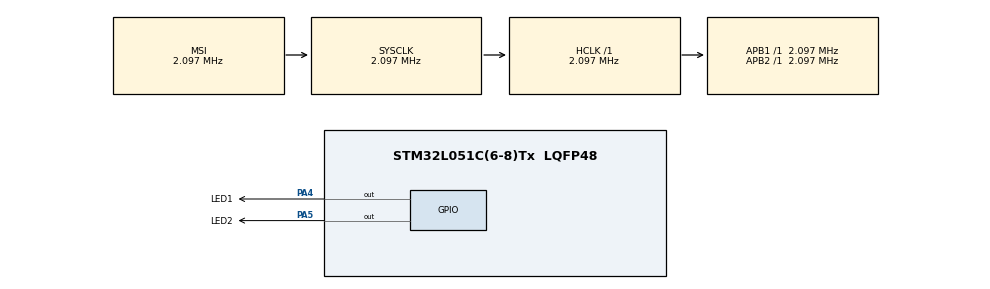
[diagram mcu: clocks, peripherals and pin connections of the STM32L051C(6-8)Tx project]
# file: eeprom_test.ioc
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Mcu.Family=STM32L0
Mcu.Name=STM32L051C(6-8)Tx
Mcu.Package=LQFP48
PA4.GPIO_Label=LED1
PA4.Signal=GPIO_Output
PA5.GPIO_Label=LED2
PA5.Signal=GPIO_Output
ProjectManager.HeapSize=0x200
ProjectManager.StackSize=0x400
ProjectManager.TargetToolchain=STM32CubeIDE
RCC.AHBFreq_Value=2097000
RCC.APB1Freq_Value=2097000
RCC.APB1TimFreq_Value=2097000
RCC.APB2Freq_Value=2097000
RCC.APB2TimFreq_Value=2097000
RCC.HSE_VALUE=8000000
RCC.HSI16_VALUE=16000000
RCC.HSI_VALUE=16000000
RCC.LSE_VALUE=32768
RCC.MSI_VALUE=2097000
RCC.SYSCLKFreq_VALUE=2097000
RCC.VCOOutputFreq_Value=48000000
board=custom

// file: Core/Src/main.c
/* USER CODE BEGIN Header */
/**
  ******************************************************************************
  * @file           : main.c
  * @brief          : Main program body
  ******************************************************************************
  * @attention
  *
  * <h2><center>&copy; Copyright (c) 2022 STMicroelectronics.
  * All rights reserved.</center></h2>
  *
  * This software component is licensed by ST under BSD 3-Clause license,
  * the "License"; You may not use this file except in compliance with the
  * License. You may obtain a copy of the License at:
  *                        opensource.org/licenses/BSD-3-Clause
  *
  ******************************************************************************
  */
/* USER CODE END Header */
#include "main.h"
#include "gpio.h"

/* USER CODE BEGIN Includes */
#include "eeprom.h"
//extern uint32_t data_to_write;
extern TStruct_write data_to_write;
uint32_t Eeprom_data1;
/* USER CODE END Includes */

void SystemClock_Config(void);

int main(void)
{

  /* MCU Configuration--------------------------------------------------------*/

  /* Reset of all peripherals, Initializes the Flash interface and the Systick. */
  HAL_Init();

  /* Configure the system clock */
  SystemClock_Config();

  /* Initialize all configured peripherals */
  MX_GPIO_Init();
  /* USER CODE BEGIN 2 */
  data_to_write.zmienna1 = 103;
 // data_to_write.zmienna2 = 104;

  Write_Registers_to_Eeprom();
  HAL_Delay(1000);
  Eeprom_data1 = CONFIG->data1;
 // Eeprom_data1 = CONFIG->data2;

  /* USER CODE END 2 */

  /* Infinite loop */
  /* USER CODE BEGIN WHILE */
  while (1)
  {
	  HAL_GPIO_WritePin(LED1_GPIO_Port, LED1_Pin, 1);
	  HAL_GPIO_WritePin(LED2_GPIO_Port, LED2_Pin, 1);
	  HAL_Delay(1000);
	  HAL_GPIO_WritePin(LED1_GPIO_Port, LED1_Pin, 0);
	  HAL_GPIO_WritePin(LED2_GPIO_Port, LED2_Pin, 0);
	  HAL_Delay(1000);

    /* USER CODE END WHILE */

  }
}

void SystemClock_Config(void)
{
  RCC_OscInitTypeDef RCC_OscInitStruct = {0};
  RCC_ClkInitTypeDef RCC_ClkInitStruct = {0};

  /** Configure the main internal regulator output voltage
  */
  __HAL_PWR_VOLTAGESCALING_CONFIG(PWR_REGULATOR_VOLTAGE_SCALE1);
  /** Initializes the RCC Oscillators according to the specified parameters
  * in the RCC_OscInitTypeDef structure.
  */
  RCC_OscInitStruct.OscillatorType = RCC_OSCILLATORTYPE_MSI;
  RCC_OscInitStruct.MSIState = RCC_MSI_ON;
  RCC_OscInitStruct.MSICalibrationValue = 0;
  RCC_OscInitStruct.MSIClockRange = RCC_MSIRANGE_5;
  RCC_OscInitStruct.PLL.PLLState = RCC_PLL_NONE;
  if (HAL_RCC_OscConfig(&RCC_OscInitStruct) != HAL_OK)
  {
    Error_Handler();
  }
  /** Initializes the CPU, AHB and APB buses clocks
  */
  RCC_ClkInitStruct.ClockType = RCC_CLOCKTYPE_HCLK|RCC_CLOCKTYPE_SYSCLK
                              |RCC_CLOCKTYPE_PCLK1|RCC_CLOCKTYPE_PCLK2;
  RCC_ClkInitStruct.SYSCLKSource = RCC_SYSCLKSOURCE_MSI;
  RCC_ClkInitStruct.AHBCLKDivider = RCC_SYSCLK_DIV1;
  RCC_ClkInitStruct.APB1CLKDivider = RCC_HCLK_DIV1;
  RCC_ClkInitStruct.APB2CLKDivider = RCC_HCLK_DIV1;

  if (HAL_RCC_ClockConfig(&RCC_ClkInitStruct, FLASH_LATENCY_0) != HAL_OK)
  {
    Error_Handler();
  }
}

void Error_Handler(void)
{
  __disable_irq();
  while (1)
  {
  }
}

/************************ (C) COPYRIGHT STMicroelectronics *****END OF FILE****/
